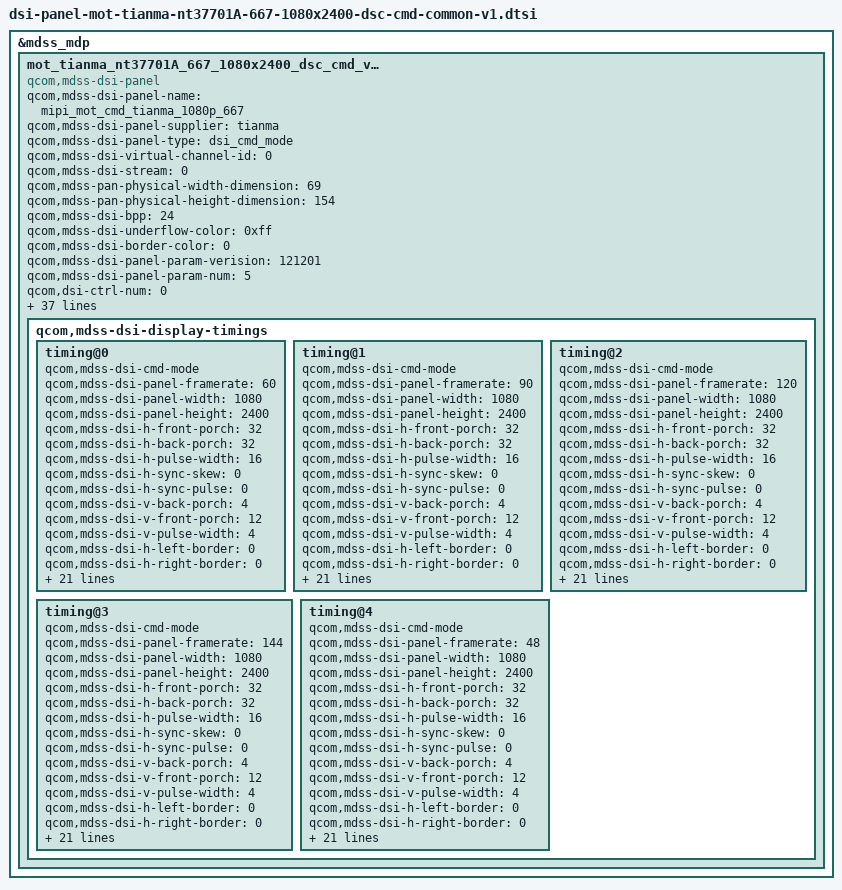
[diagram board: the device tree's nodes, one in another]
/* Copyright (c) 2019-2020, The Linux Foundation. All rights reserved.
 *
 * This program is free software; you can redistribute it and/or modify
 * it under the terms of the GNU General Public License version 2 and
 * only version 2 as published by the Free Software Foundation.
 *
 * This program is distributed in the hope that it will be useful,
 * but WITHOUT ANY WARRANTY; without even the implied warranty of
 * MERCHANTABILITY or FITNESS FOR A PARTICULAR PURPOSE.  See the
 * GNU General Public License for more details.
 */
&mdss_mdp {
mot_tianma_nt37701A_667_1080x2400_dsc_cmd_v1: qcom,mdss_dsi_mot_tianma_nt37701A_667_1080x2400_dsc_cmd_v1 {
compatible = "qcom,mdss-dsi-panel";
qcom,mdss-dsi-panel-name = "mipi_mot_cmd_tianma_1080p_667";
qcom,mdss-dsi-panel-supplier = "tianma";
qcom,mdss-dsi-panel-type = "dsi_cmd_mode";
qcom,mdss-dsi-virtual-channel-id = <0>;
qcom,mdss-dsi-stream = <0>;
qcom,mdss-pan-physical-width-dimension = <69>;
qcom,mdss-pan-physical-height-dimension = <154>;
qcom,mdss-dsi-bpp = <24>;
qcom,mdss-dsi-underflow-color = <0xff>;
qcom,mdss-dsi-border-color = <0>;
qcom,mdss-dsi-panel-param-verision = <121201>;
qcom,mdss-dsi-panel-param-num = <5>;

qcom,dsi-ctrl-num = <0>;
qcom,dsi-phy-num = <0>;

qcom,mdss-dsi-traffic-mode = "burst_mode";
qcom,mdss-dsi-bllp-eof-power-mode;
qcom,mdss-dsi-bllp-power-mode;
qcom,mdss-dsi-lane-0-state;
qcom,mdss-dsi-lane-1-state;
qcom,mdss-dsi-lane-2-state;
qcom,mdss-dsi-lane-3-state;

qcom,mdss-dsi-dma-trigger = "trigger_sw";
qcom,mdss-dsi-mdp-trigger = "none";
qcom,mdss-dsi-reset-sequence = <0 11>, <1 1>, <0 1>, <1 11>;
qcom,mdss-dsi-lp11-init;
qcom,mdss-dsi-tx-eot-append;
qcom,mdss-dsi-te-pin-select = <1>;
qcom,mdss-dsi-te-dcs-command = <1>;
qcom,mdss-dsi-te-using-te-pin;

//qcom,bklt-dcs-2bytes-enabled;
qcom,mdss-dsi-bl-min-level = <3>;
qcom,mdss-dsi-bl-max-level = <2047>;
qcom,mdss-dsi-bl-pmic-control-type = "bl_ctrl_dcs";

qcom,mdss-dsi-panel-hdr-enabled;
qcom,mdss-dsi-panel-hdr-color-primaries = <14500 15500 32000
	        17000 15500 30000 8000 3000>;
qcom,mdss-dsi-panel-peak-brightness = <4200000>;

qcom,mdss-dsi-panel-blackness-level = <3230>;

qcom,mdss-dsi-hbm-on-command = [
		39 01 00 00 00 00 03 51 0F FF];
qcom,mdss-dsi-hbm-off-command = [
		39 01 00 00 00 00 03 51 0C 7D];

//qcom,mdss-dsi-acl-on-command = [
//		39 01 00 00 00 00 06 F0 55 AA 52 08 00
//		15 00 00 00 00 00 02 B0 0C
//		15 01 00 00 00 00 02 55 05];
//qcom,mdss-dsi-acl-off-command = [
//		15 01 00 00 00 00 02 55 00];

qcom,mdss-dsi-dc-off-command = [
		39 00 00 00 00 00 06 F0 55 AA 52 08 00
		39 00 00 40 00 00 02 B2 11
		39 00 00 00 00 00 25 B3 00 09 00 E1 00 E1 01 EF 01 EF 02 D2 02 D2 04 3B 04 3B 05 08 05 08 05 09 05 09 07 B1 07 B1 0C 7D 0C 7D 0F FF

		39 00 00 40 00 00 02 6F 0F
		39 00 00 00 00 00 07 B2 30 20 85 08 25 08

		39 00 00 00 00 00 06 F0 55 AA 52 08 04 //normal gain 60Hz, please replace by page4 D200-D24A read from DDIC
		39 00 00 00 00 00 4C D2 40 21 35 16 20 50 3f 39 28 15 a8 48 2A 35 25 a0 58 55 48 38 90 6b 68 50 10
					40 21 35 16 20 50 3f 39 28 15 a8 48 2A 35 25 a0 58 55 48 38 90 6b 68 50 10
					40 21 35 16 20 50 3f 39 28 15 a8 48 2A 35 25 a0 58 55 48 38 90 6b 68 50 10

		39 00 00 00 00 00 02 58 00//01:DC Gain ; 00:Normal Gain
		];
qcom,mdss-dsi-dc-off-command-state = "dsi_hs_mode";
qcom,mdss-dsi-dc-on-command = [
		39 00 00 00 00 00 06 F0 55 AA 52 08 00
		39 00 00 40 00 00 02 B2 91
		39 00 00 40 00 00 02 6F 0F
		39 00 00 40 00 00 07 B2 00 20 00 00 00 00 //pulse number
		39 00 00 00 00 00 25 B3 00 00 00 00 00 00 00 00 00 00 00 00 00 00 00 00 00 00 00 00 00 00 00 00 05 09 07 B1 07 B1 0C 7D 0C 7D 0F FF //dbv th
		39 00 00 00 00 00 06 F0 55 AA 52 08 04 //DC gain 60Hz, please replace by page4 E700-E74A read from DDIC
		39 00 00 00 00 00 4C D2 35 35 35 16 20 39 39 39 28 15 2A 2A 2A 35 25 55 55 55 48 38 68 68 68 50 10
					35 35 35 16 20 39 39 39 28 15 2A 2A 2A 35 25 55 55 55 48 38 68 68 68 50 10
					35 35 35 16 20 39 39 39 28 15 2A 2A 2A 35 25 55 55 55 48 38 68 68 68 50 10

		39 00 00 00 00 00 02 58 01//01:DC Gain ; 00:Normal Gain
		];
qcom,mdss-dsi-dc-on-command-state = "dsi_hs_mode";
qcom,mdss-dsi-display-timings {
	timing@0{
		qcom,mdss-dsi-cmd-mode;
		qcom,mdss-dsi-panel-framerate = <60>;
		qcom,mdss-dsi-panel-width = <1080>;
		qcom,mdss-dsi-panel-height = <2400>;
		qcom,mdss-dsi-h-front-porch = <32>;
		qcom,mdss-dsi-h-back-porch = <32>;
		qcom,mdss-dsi-h-pulse-width = <16>;
		qcom,mdss-dsi-h-sync-skew = <0>;
		qcom,mdss-dsi-h-sync-pulse = <0>;
		qcom,mdss-dsi-v-back-porch = <4>;
		qcom,mdss-dsi-v-front-porch = <12>;
		qcom,mdss-dsi-v-pulse-width = <4>;
		qcom,mdss-dsi-h-left-border = <0>;
		qcom,mdss-dsi-h-right-border = <0>;
		qcom,mdss-dsi-v-top-border = <0>;
		qcom,mdss-dsi-v-bottom-border = <0>;
		qcom,mdss-dsi-panel-jitter = <0x20 0xa>; /* 90fps +/- 2 */
		qcom,mdss-dsi-timing-switch-command = [
			15 01 00 00 10 00 02 2F 01 //01=60HZ；02=120HZ；03=90HZ；04=144HZ 08=48HZ
		];

		qcom,mdss-dsi-on-command = [
			39 01 00 00 00 00 06 F0 55 AA 52 08 00
			39 01 00 00 00 00 02 6F 05
			39 01 00 00 00 00 05 B5 7F 49 20 50
			39 01 00 00 00 00 02 6F 10
			39 01 00 00 00 00 06 B5 20 20 20 20 20
			39 01 00 00 00 00 02 6F 1C
			39 01 00 00 00 00 06 C0 15 27 38 00 49
			39 01 00 00 00 00 02 6F 2C
			39 01 00 00 00 00 03 B3 09 A0
			39 01 00 00 00 00 02 5F 80

			39 01 00 00 00 00 05 3B 00 10 00 04
			39 01 00 00 00 00 02 90 01
			39 01 00 00 00 00 13 91 89 28 00 0C C2 00 03 1C 01 7E 00 0F 08 BB 04 3D 10 F0
			39 01 00 00 00 00 02 03 01
			39 01 00 00 00 00 03 51 00 00
			39 01 00 00 00 00 02 53 20
			39 01 00 00 00 00 02 35 00
			39 01 00 00 00 00 05 2A 00 00 04 37
			39 01 00 00 00 00 05 2B 00 00 09 5F
			39 01 00 00 00 00 02 2F 01 //01=60HZ；02=120HZ；03=90HZ；04=144HZ 08=48HZ
			05 01 00 00 78 00 01 11
			39 01 00 00 00 00 06 F0 55 AA 52 08 08
			39 01 00 00 00 00 06 E1 A1 03 03 03 00
			05 01 00 00 00 00 01 29];
		qcom,mdss-dsi-off-command = [
			05 01 00 00 00 00 01 28		/* display_off */
			05 01 00 00 78 00 01 10];	/* enter sleep mode */

		qcom,mdss-dsi-on-command-state = "dsi_lp_mode";
		qcom,mdss-dsi-off-command-state = "dsi_lp_mode";
		qcom,mdss-dsi-timing-switch-command-state =
			"dsi_lp_mode";
		qcom,compression-mode = "dsc";
		/* Why QCOM doesn't use this, even it used 2 encoder
		 * as for that dsi_sw43404_amoled_cmd, for ex */
		/* qcom,mdss-dsc-encoders = <2>; */
		qcom,mdss-dsc-version = <0x11>;
		qcom,mdss-dsc-slice-height = <12>;
		qcom,mdss-dsc-slice-width = <1080>;
		qcom,mdss-dsc-slice-per-pkt = <1>;
		qcom,mdss-dsc-bit-per-component = <10>;
		qcom,mdss-dsc-bit-per-pixel = <8>;
		qcom,mdss-dsc-block-prediction-enable;
	};
	timing@1{
		qcom,mdss-dsi-cmd-mode;
		qcom,mdss-dsi-panel-framerate = <90>;
		qcom,mdss-dsi-panel-width = <1080>;
		qcom,mdss-dsi-panel-height = <2400>;
		qcom,mdss-dsi-h-front-porch = <32>;
		qcom,mdss-dsi-h-back-porch = <32>;
		qcom,mdss-dsi-h-pulse-width = <16>;
		qcom,mdss-dsi-h-sync-skew = <0>;
		qcom,mdss-dsi-h-sync-pulse = <0>;
		qcom,mdss-dsi-v-back-porch = <4>;
		qcom,mdss-dsi-v-front-porch = <12>;
		qcom,mdss-dsi-v-pulse-width = <4>;
		qcom,mdss-dsi-h-left-border = <0>;
		qcom,mdss-dsi-h-right-border = <0>;
		qcom,mdss-dsi-v-top-border = <0>;
		qcom,mdss-dsi-v-bottom-border = <0>;
		qcom,mdss-dsi-panel-jitter = <0x20 0xa>; /* 90fps +/- 2 */
		qcom,mdss-dsi-timing-switch-command = [
			15 01 00 00 10 00 02 2F 03 //01=60HZ；02=120HZ；03=90HZ；04=144HZ 08=48HZ
		];

		qcom,mdss-dsi-on-command = [
			39 01 00 00 00 00 06 F0 55 AA 52 08 00
			39 01 00 00 00 00 02 6F 05
			39 01 00 00 00 00 05 B5 7F 49 20 50
			39 01 00 00 00 00 02 6F 10
			39 01 00 00 00 00 06 B5 20 20 20 20 20
			39 01 00 00 00 00 02 6F 1C
			39 01 00 00 00 00 06 C0 15 27 38 00 49
			39 01 00 00 00 00 02 6F 2C
			39 01 00 00 00 00 03 B3 09 A0

			39 01 00 00 00 00 02 5F 80

			39 01 00 00 00 00 05 3B 00 10 00 04
			39 01 00 00 00 00 02 90 01
			39 01 00 00 00 00 13 91 89 28 00 0C C2 00 03 1C 01 7E 00 0F 08 BB 04 3D 10 F0
			39 01 00 00 00 00 02 03 01
			39 01 00 00 00 00 03 51 00 00
			39 01 00 00 00 00 02 53 20
			39 01 00 00 00 00 02 35 00
			39 01 00 00 00 00 05 2A 00 00 04 37
			39 01 00 00 00 00 05 2B 00 00 09 5F
			39 01 00 00 00 00 02 2F 03 //01=60HZ；02=120HZ；03=90HZ；04=144HZ 08=48HZ
			05 01 00 00 78 00 01 11
			39 01 00 00 00 00 06 F0 55 AA 52 08 08
			39 01 00 00 00 00 06 E1 A1 03 03 03 00
			05 01 00 00 00 00 01 29];
		qcom,mdss-dsi-off-command = [
			05 01 00 00 00 00 01 28		/* display_off */
			05 01 00 00 78 00 01 10];	/* enter sleep mode */

		qcom,mdss-dsi-on-command-state = "dsi_lp_mode";
		qcom,mdss-dsi-off-command-state = "dsi_lp_mode";
		qcom,mdss-dsi-timing-switch-command-state =
			"dsi_lp_mode";
		qcom,compression-mode = "dsc";
		/* Why QCOM doesn't use this, even it used 2 encoder
		 * as for that dsi_sw43404_amoled_cmd, for ex */
		/* qcom,mdss-dsc-encoders = <2>; */
		qcom,mdss-dsc-version = <0x11>;
		qcom,mdss-dsc-slice-height = <12>;
		qcom,mdss-dsc-slice-width = <1080>;
		qcom,mdss-dsc-slice-per-pkt = <1>;
		qcom,mdss-dsc-bit-per-component = <10>;
		qcom,mdss-dsc-bit-per-pixel = <8>;
		qcom,mdss-dsc-block-prediction-enable;
	};
	timing@2{
		qcom,mdss-dsi-cmd-mode;
		qcom,mdss-dsi-panel-framerate = <120>;
		qcom,mdss-dsi-panel-width = <1080>;
		qcom,mdss-dsi-panel-height = <2400>;
		qcom,mdss-dsi-h-front-porch = <32>;
		qcom,mdss-dsi-h-back-porch = <32>;
		qcom,mdss-dsi-h-pulse-width = <16>;
		qcom,mdss-dsi-h-sync-skew = <0>;
		qcom,mdss-dsi-h-sync-pulse = <0>;
		qcom,mdss-dsi-v-back-porch = <4>;
		qcom,mdss-dsi-v-front-porch = <12>;
		qcom,mdss-dsi-v-pulse-width = <4>;
		qcom,mdss-dsi-h-left-border = <0>;
		qcom,mdss-dsi-h-right-border = <0>;
		qcom,mdss-dsi-v-top-border = <0>;
		qcom,mdss-dsi-v-bottom-border = <0>;
		qcom,mdss-dsi-panel-jitter = <0x20 0xa>; /* 90fps +/- 2 */
		qcom,mdss-dsi-timing-switch-command = [
			15 01 00 00 10 00 02 2F 02 //01=60HZ；02=120HZ；03=90HZ；04=144HZ 08=48HZ
		];

		qcom,mdss-dsi-on-command = [
			39 00 00 00 00 00 06 F0 55 AA 52 08 00
			39 00 00 00 00 00 02 6F 05
			39 00 00 00 00 00 05 B5 7F 49 20 50
			39 00 00 00 00 00 02 6F 10
			39 00 00 00 00 00 06 B5 20 20 20 20 20
			39 01 00 00 00 00 02 6F 1C
			39 01 00 00 00 00 06 C0 15 27 38 00 49
			39 01 00 00 00 00 02 6F 2C
			39 01 00 00 00 00 03 B3 09 A0

			39 01 00 00 00 00 02 5F 80

			39 01 00 00 00 00 05 3B 00 10 00 04
			39 01 00 00 00 00 02 90 01
			39 01 00 00 00 00 13 91 89 28 00 0C C2 00 03 1C 01 7E 00 0F 08 BB 04 3D 10 F0
			39 01 00 00 00 00 02 03 01
			39 01 00 00 00 00 03 51 00 00
			39 01 00 00 00 00 02 53 20
			39 01 00 00 00 00 02 35 00
			39 01 00 00 00 00 05 2A 00 00 04 37
			39 01 00 00 00 00 05 2B 00 00 09 5F
			39 01 00 00 00 00 02 2F 02 //01=60HZ；02=120HZ；03=90HZ；04=144HZ 08=48HZ
			05 01 00 00 78 00 01 11
			39 01 00 00 00 00 06 F0 55 AA 52 08 08
			39 01 00 00 00 00 06 E1 A1 03 03 03 00
			05 01 00 00 00 00 01 29];
		qcom,mdss-dsi-off-command = [
			05 01 00 00 00 00 01 28		/* display_off */
			05 01 00 00 78 00 01 10];	/* enter sleep mode */

		qcom,mdss-dsi-on-command-state = "dsi_lp_mode";
		qcom,mdss-dsi-off-command-state = "dsi_lp_mode";
		qcom,mdss-dsi-timing-switch-command-state =
			"dsi_lp_mode";
		qcom,compression-mode = "dsc";
		/* Why QCOM doesn't use this, even it used 2 encoder
		 * as for that dsi_sw43404_amoled_cmd, for ex */
		/* qcom,mdss-dsc-encoders = <2>; */
		qcom,mdss-dsc-version = <0x11>;
		qcom,mdss-dsc-slice-height = <12>;
		qcom,mdss-dsc-slice-width = <1080>;
		qcom,mdss-dsc-slice-per-pkt = <1>;
		qcom,mdss-dsc-bit-per-component = <10>;
		qcom,mdss-dsc-bit-per-pixel = <8>;
		qcom,mdss-dsc-block-prediction-enable;
	};
	timing@3{
		qcom,mdss-dsi-cmd-mode;
		qcom,mdss-dsi-panel-framerate = <144>;
		qcom,mdss-dsi-panel-width = <1080>;
		qcom,mdss-dsi-panel-height = <2400>;
		qcom,mdss-dsi-h-front-porch = <32>;
		qcom,mdss-dsi-h-back-porch = <32>;
		qcom,mdss-dsi-h-pulse-width = <16>;
		qcom,mdss-dsi-h-sync-skew = <0>;
		qcom,mdss-dsi-h-sync-pulse = <0>;
		qcom,mdss-dsi-v-back-porch = <4>;
		qcom,mdss-dsi-v-front-porch = <12>;
		qcom,mdss-dsi-v-pulse-width = <4>;
		qcom,mdss-dsi-h-left-border = <0>;
		qcom,mdss-dsi-h-right-border = <0>;
		qcom,mdss-dsi-v-top-border = <0>;
		qcom,mdss-dsi-v-bottom-border = <0>;
		qcom,mdss-dsi-panel-jitter = <0x20 0xa>; /* 90fps +/- 2 */
		qcom,mdss-dsi-timing-switch-command = [
			15 01 00 00 10 00 02 2F 04 //01=60HZ；02=120HZ；03=90HZ；04=144HZ 08=48HZ
		];

		qcom,mdss-dsi-on-command = [
			39 01 00 00 00 00 06 F0 55 AA 52 08 00
			39 01 00 00 00 00 02 6F 05
			39 01 00 00 00 00 05 B5 7F 49 20 50
			39 01 00 00 00 00 02 6F 10
			39 01 00 00 00 00 06 B5 20 20 20 20 20
			39 01 00 00 00 00 02 6F 1C
			39 01 00 00 00 00 06 C0 15 27 38 00 49
			39 01 00 00 00 00 02 6F 2C
			39 01 00 00 00 00 03 B3 09 A0

			39 01 00 00 00 00 02 5F 80

			39 01 00 00 00 00 05 3B 00 10 00 04
			39 01 00 00 00 00 02 90 01
			39 01 00 00 00 00 13 91 89 28 00 0C C2 00 03 1C 01 7E 00 0F 08 BB 04 3D 10 F0
			39 01 00 00 00 00 02 03 01
			39 01 00 00 00 00 03 51 00 00
			39 01 00 00 00 00 02 53 20
			39 01 00 00 00 00 02 35 00
			39 01 00 00 00 00 05 2A 00 00 04 37
			39 01 00 00 00 00 05 2B 00 00 09 5F
			39 01 00 00 00 00 02 2F 04 //01=60HZ；02=120HZ；03=90HZ；04=144HZ 08=48HZ
			05 01 00 00 78 00 01 11
			39 01 00 00 00 00 06 F0 55 AA 52 08 08
			39 01 00 00 00 00 06 E1 A1 03 03 03 00
			05 01 00 00 00 00 01 29];
		qcom,mdss-dsi-off-command = [
			05 01 00 00 00 00 01 28		/* display_off */
			05 01 00 00 78 00 01 10];	/* enter sleep mode */

		qcom,mdss-dsi-on-command-state = "dsi_lp_mode";
		qcom,mdss-dsi-off-command-state = "dsi_lp_mode";
		qcom,mdss-dsi-timing-switch-command-state =
			"dsi_lp_mode";
		qcom,compression-mode = "dsc";
		/* Why QCOM doesn't use this, even it used 2 encoder
		 * as for that dsi_sw43404_amoled_cmd, for ex */
		/* qcom,mdss-dsc-encoders = <2>; */
		qcom,mdss-dsc-version = <0x11>;
		qcom,mdss-dsc-slice-height = <12>;
		qcom,mdss-dsc-slice-width = <1080>;
		qcom,mdss-dsc-slice-per-pkt = <1>;
		qcom,mdss-dsc-bit-per-component = <10>;
		qcom,mdss-dsc-bit-per-pixel = <8>;
		qcom,mdss-dsc-block-prediction-enable;
	};
	timing@4{
		qcom,mdss-dsi-cmd-mode;
		qcom,mdss-dsi-panel-framerate = <48>;
		qcom,mdss-dsi-panel-width = <1080>;
		qcom,mdss-dsi-panel-height = <2400>;
		qcom,mdss-dsi-h-front-porch = <32>;
		qcom,mdss-dsi-h-back-porch = <32>;
		qcom,mdss-dsi-h-pulse-width = <16>;
		qcom,mdss-dsi-h-sync-skew = <0>;
		qcom,mdss-dsi-h-sync-pulse = <0>;
		qcom,mdss-dsi-v-back-porch = <4>;
		qcom,mdss-dsi-v-front-porch = <12>;
		qcom,mdss-dsi-v-pulse-width = <4>;
		qcom,mdss-dsi-h-left-border = <0>;
		qcom,mdss-dsi-h-right-border = <0>;
		qcom,mdss-dsi-v-top-border = <0>;
		qcom,mdss-dsi-v-bottom-border = <0>;
		qcom,mdss-dsi-panel-jitter = <0x20 0xa>; /* 90fps +/- 2 */
		qcom,mdss-dsi-timing-switch-command = [
			15 01 00 00 10 00 02 2F 08 //01=60HZ；02=120HZ；03=90HZ；04=144HZ 08=48HZ
		];

		qcom,mdss-dsi-on-command = [
			39 01 00 00 00 00 06 F0 55 AA 52 08 00
			39 01 00 00 00 00 02 6F 05
			39 01 00 00 00 00 05 B5 7F 49 20 50
			39 01 00 00 00 00 02 6F 10
			39 01 00 00 00 00 06 B5 20 20 20 20 20
			39 01 00 00 00 00 02 6F 1C
			39 01 00 00 00 00 06 C0 15 27 38 00 49
			39 01 00 00 00 00 02 6F 2C
			39 01 00 00 00 00 03 B3 09 A0
			39 01 00 00 00 00 02 5F 80

			39 01 00 00 00 00 05 3B 00 10 00 04
			39 01 00 00 00 00 02 90 01
			39 01 00 00 00 00 13 91 89 28 00 0C C2 00 03 1C 01 7E 00 0F 08 BB 04 3D 10 F0
			39 01 00 00 00 00 02 03 01
			39 01 00 00 00 00 03 51 00 00
			39 01 00 00 00 00 02 53 20
			39 01 00 00 00 00 02 35 00
			39 01 00 00 00 00 05 2A 00 00 04 37
			39 01 00 00 00 00 05 2B 00 00 09 5F
			39 01 00 00 00 00 02 2F 08 //01=60HZ；02=120HZ；03=90HZ；04=144HZ 08=48HZ
			05 01 00 00 78 00 01 11
			39 01 00 00 00 00 06 F0 55 AA 52 08 08
			39 01 00 00 00 00 06 E1 A1 03 03 03 00
			05 01 00 00 00 00 01 29];
		qcom,mdss-dsi-off-command = [
			05 01 00 00 00 00 01 28		/* display_off */
			05 01 00 00 78 00 01 10];	/* enter sleep mode */

		qcom,mdss-dsi-on-command-state = "dsi_lp_mode";
		qcom,mdss-dsi-off-command-state = "dsi_lp_mode";
		qcom,mdss-dsi-timing-switch-command-state =
			"dsi_lp_mode";
		qcom,compression-mode = "dsc";
		/* Why QCOM doesn't use this, even it used 2 encoder
		 * as for that dsi_sw43404_amoled_cmd, for ex */
		/* qcom,mdss-dsc-encoders = <2>; */
		qcom,mdss-dsc-version = <0x11>;
		qcom,mdss-dsc-slice-height = <12>;
		qcom,mdss-dsc-slice-width = <1080>;
		qcom,mdss-dsc-slice-per-pkt = <1>;
		qcom,mdss-dsc-bit-per-component = <10>;
		qcom,mdss-dsc-bit-per-pixel = <8>;
		qcom,mdss-dsc-block-prediction-enable;
	};
};

};

};
